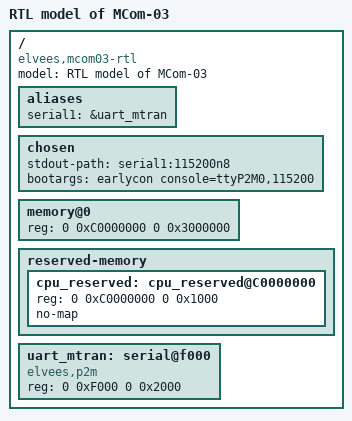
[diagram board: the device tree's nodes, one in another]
// SPDX-License-Identifier: GPL-2.0+
/*
 * Copyright 2019 RnD Center "ELVEES", JSC
 */

/dts-v1/;

#include "mcom03.dtsi"

/ {
	model = "RTL model of MCom-03";
	compatible = "elvees,mcom03-rtl";

	aliases {
		serial1 = &uart_mtran;
	};

	chosen {
		stdout-path = "serial1:115200n8";
		bootargs = "earlycon console=ttyP2M0,115200";
	};

	memory@0 {
		device_type = "memory";
		reg = <0 0xC0000000 0 0x3000000>; /* 48 MiB */
	};

	reserved-memory {
		#address-cells = <2>;
		#size-cells = <2>;
		ranges;

		cpu_reserved: cpu_reserved@C0000000 {
			reg = <0 0xC0000000 0 0x1000>;
			no-map;
		};
	};

	uart_mtran: serial@f000 {
		compatible = "elvees,p2m";
		reg = <0 0xF000 0 0x2000>;
	};
};
